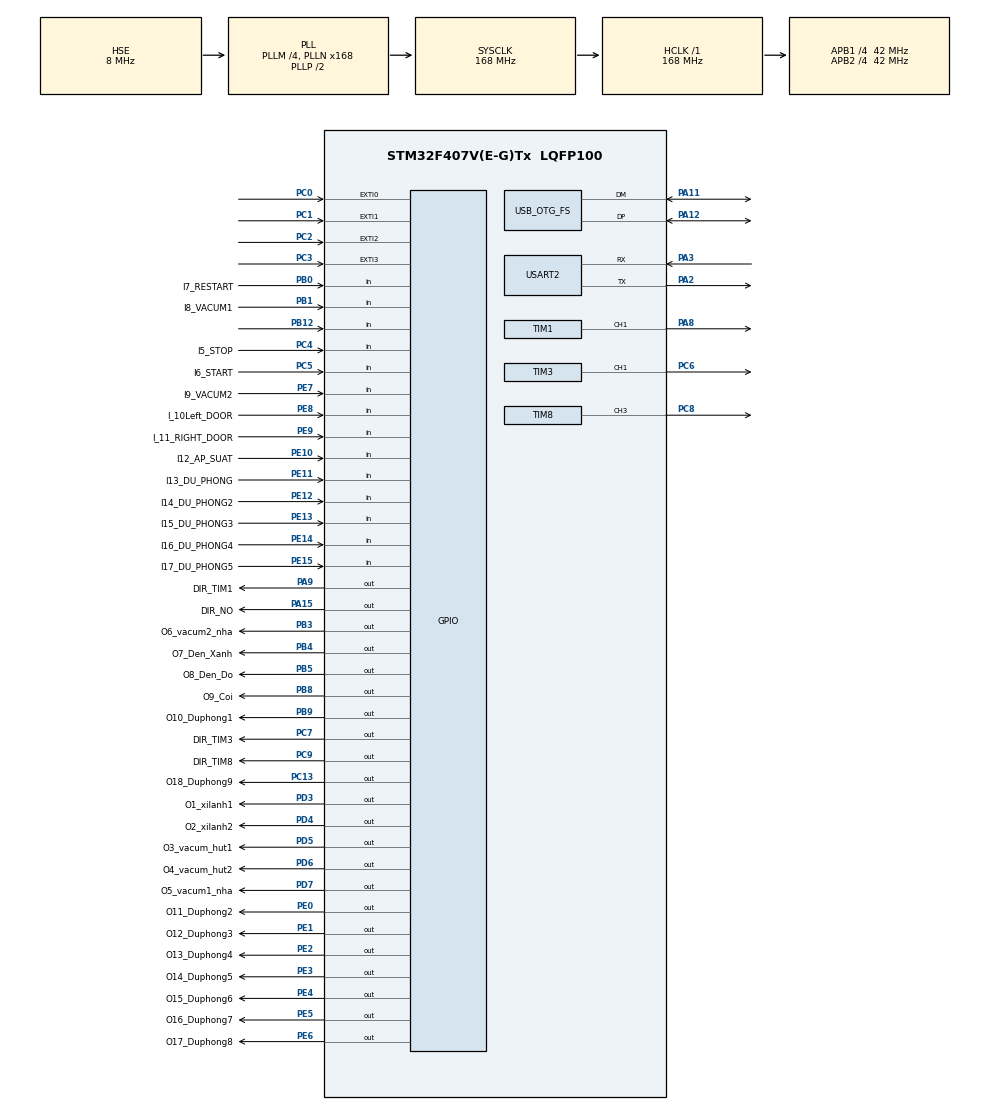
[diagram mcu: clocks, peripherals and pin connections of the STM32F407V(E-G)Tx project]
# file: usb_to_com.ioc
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Dma.Request0=USART2_RX
Dma.Request1=USART2_TX
Dma.USART2_RX.0.Direction=DMA_PERIPH_TO_MEMORY
Dma.USART2_RX.0.FIFOMode=DMA_FIFOMODE_DISABLE
Dma.USART2_RX.0.Instance=DMA1_Stream5
Dma.USART2_RX.0.MemDataAlignment=DMA_MDATAALIGN_BYTE
Dma.USART2_RX.0.MemInc=DMA_MINC_ENABLE
Dma.USART2_RX.0.Mode=DMA_NORMAL
Dma.USART2_RX.0.PeriphDataAlignment=DMA_PDATAALIGN_BYTE
Dma.USART2_RX.0.PeriphInc=DMA_PINC_DISABLE
Dma.USART2_RX.0.Priority=DMA_PRIORITY_LOW
Dma.USART2_TX.1.Direction=DMA_MEMORY_TO_PERIPH
Dma.USART2_TX.1.FIFOMode=DMA_FIFOMODE_DISABLE
Dma.USART2_TX.1.Instance=DMA1_Stream6
Dma.USART2_TX.1.MemDataAlignment=DMA_MDATAALIGN_BYTE
Dma.USART2_TX.1.MemInc=DMA_MINC_ENABLE
Dma.USART2_TX.1.Mode=DMA_NORMAL
Dma.USART2_TX.1.PeriphDataAlignment=DMA_PDATAALIGN_BYTE
Dma.USART2_TX.1.PeriphInc=DMA_PINC_DISABLE
Dma.USART2_TX.1.Priority=DMA_PRIORITY_LOW
Mcu.Family=STM32F4
Mcu.Name=STM32F407V(E-G)Tx
Mcu.Package=LQFP100
NVIC.DMA1_Stream5_IRQn=true\:1\:0\:true\:false\:true\:false\:true\:true
NVIC.DMA1_Stream6_IRQn=true\:1\:0\:true\:false\:true\:false\:true\:true
NVIC.EXTI0_IRQn=true\:0\:0\:false\:false\:true\:true\:true\:true
NVIC.EXTI1_IRQn=true\:0\:0\:false\:false\:true\:true\:true\:true
NVIC.EXTI2_IRQn=true\:0\:0\:false\:false\:true\:true\:true\:true
NVIC.EXTI3_IRQn=true\:0\:0\:false\:false\:true\:true\:true\:true
NVIC.OTG_FS_IRQn=true\:1\:0\:true\:false\:true\:false\:true\:true
NVIC.PriorityGroup=NVIC_PRIORITYGROUP_4
NVIC.TIM7_IRQn=true\:0\:0\:true\:false\:true\:true\:true\:true
NVIC.USART2_IRQn=true\:1\:0\:true\:false\:true\:true\:true\:true
PA11.Mode=Device_Only
PA11.Signal=USB_OTG_FS_DM
PA12.Mode=Device_Only
PA12.Signal=USB_OTG_FS_DP
PA13.Mode=Serial_Wire
PA13.Signal=SYS_JTMS-SWDIO
PA14.Mode=Serial_Wire
PA14.Signal=SYS_JTCK-SWCLK
PA15.GPIO_Label=DIR_NO
PA15.Signal=GPIO_Output
PA2.Mode=Asynchronous
PA2.Signal=USART2_TX
PA3.Mode=Asynchronous
PA3.Signal=USART2_RX
PA8.GPIO_PuPd=GPIO_NOPULL
PA8.GPIO_Speed=GPIO_SPEED_FREQ_HIGH
PA8.Signal=S_TIM1_CH1
PA9.GPIO_Label=DIR_TIM1
PA9.GPIO_Speed=GPIO_SPEED_FREQ_HIGH
PA9.Signal=GPIO_Output
PB0.GPIO_Label=I7_RESTART
PB0.Signal=GPIO_Input
PB1.GPIO_Label=I8_VACUM1
PB1.Signal=GPIO_Input
PB12.Signal=GPIO_Input
PB3.GPIO_Label=O6_vacum2_nha
PB3.GPIO_PuPd=GPIO_PULLUP
PB3.PinState=GPIO_PIN_SET
PB3.Signal=GPIO_Output
PB4.GPIO_Label=O7_Den_Xanh
PB4.GPIO_PuPd=GPIO_PULLUP
PB4.PinState=GPIO_PIN_SET
PB4.Signal=GPIO_Output
PB5.GPIO_Label=O8_Den_Do
PB5.GPIO_PuPd=GPIO_PULLUP
PB5.PinState=GPIO_PIN_SET
PB5.Signal=GPIO_Output
PB8.GPIO_Label=O9_Coi
PB8.GPIO_PuPd=GPIO_PULLUP
PB8.PinState=GPIO_PIN_SET
PB8.Signal=GPIO_Output
PB9.GPIO_Label=O10_Duphong1
PB9.GPIO_PuPd=GPIO_PULLUP
PB9.PinState=GPIO_PIN_SET
PB9.Signal=GPIO_Output
PC0.GPIO_ModeDefaultEXTI=GPIO_MODE_IT_RISING
PC0.Signal=GPXTI0
PC1.GPIO_ModeDefaultEXTI=GPIO_MODE_IT_RISING
PC1.Signal=GPXTI1
PC13-ANTI_TAMP.GPIO_Label=O18_Duphong9
PC13-ANTI_TAMP.GPIO_PuPd=GPIO_PULLUP
PC13-ANTI_TAMP.PinState=GPIO_PIN_SET
PC13-ANTI_TAMP.Signal=GPIO_Output
PC2.GPIO_ModeDefaultEXTI=GPIO_MODE_IT_RISING
PC2.Signal=GPXTI2
PC3.Signal=GPXTI3
PC4.GPIO_Label=I5_STOP
PC4.Signal=GPIO_Input
PC5.GPIO_Label=I6_START
PC5.Signal=GPIO_Input
PC6.GPIO_PuPd=GPIO_NOPULL
PC6.GPIO_Speed=GPIO_SPEED_FREQ_HIGH
PC6.Signal=S_TIM3_CH1
PC7.GPIO_Label=DIR_TIM3
PC7.GPIO_Speed=GPIO_SPEED_FREQ_HIGH
PC7.Signal=GPIO_Output
PC8.GPIO_ModeDefaultPP=GPIO_MODE_AF_PP
PC8.GPIO_PuPd=GPIO_NOPULL
PC8.GPIO_Speed=GPIO_SPEED_FREQ_HIGH
PC8.Signal=S_TIM8_CH3
PC9.GPIO_Label=DIR_TIM8
PC9.GPIO_Speed=GPIO_SPEED_FREQ_HIGH
PC9.Signal=GPIO_Output
PD3.GPIO_Label=O1_xilanh1
PD3.GPIO_PuPd=GPIO_PULLUP
PD3.PinState=GPIO_PIN_SET
PD3.Signal=GPIO_Output
PD4.GPIO_Label=O2_xilanh2
PD4.GPIO_PuPd=GPIO_PULLUP
PD4.PinState=GPIO_PIN_SET
PD4.Signal=GPIO_Output
PD5.GPIO_Label=O3_vacum_hut1
PD5.GPIO_PuPd=GPIO_PULLUP
PD5.PinState=GPIO_PIN_SET
PD5.Signal=GPIO_Output
PD6.GPIO_Label=O4_vacum_hut2
PD6.GPIO_PuPd=GPIO_PULLUP
PD6.PinState=GPIO_PIN_SET
PD6.Signal=GPIO_Output
PD7.GPIO_Label=O5_vacum1_nha
PD7.GPIO_PuPd=GPIO_PULLUP
PD7.PinState=GPIO_PIN_SET
PD7.Signal=GPIO_Output
PE0.GPIO_Label=O11_Duphong2
PE0.GPIO_PuPd=GPIO_PULLUP
PE0.PinState=GPIO_PIN_SET
PE0.Signal=GPIO_Output
PE1.GPIO_Label=O12_Duphong3
PE1.GPIO_PuPd=GPIO_PULLUP
PE1.PinState=GPIO_PIN_SET
PE1.Signal=GPIO_Output
PE10.GPIO_Label=I12_AP_SUAT
PE10.GPIO_PuPd=GPIO_NOPULL
PE10.Signal=GPIO_Input
PE11.GPIO_Label=I13_DU_PHONG
PE11.GPIO_PuPd=GPIO_NOPULL
PE11.Signal=GPIO_Input
PE12.GPIO_Label=I14_DU_PHONG2
PE12.GPIO_PuPd=GPIO_NOPULL
PE12.Signal=GPIO_Input
PE13.GPIO_Label=I15_DU_PHONG3
PE13.Signal=GPIO_Input
PE14.GPIO_Label=I16_DU_PHONG4
PE14.Signal=GPIO_Input
PE15.GPIO_Label=I17_DU_PHONG5
PE15.Signal=GPIO_Input
PE2.GPIO_Label=O13_Duphong4
PE2.GPIO_PuPd=GPIO_PULLUP
PE2.PinState=GPIO_PIN_SET
PE2.Signal=GPIO_Output
PE3.GPIO_Label=O14_Duphong5
PE3.GPIO_PuPd=GPIO_PULLUP
PE3.PinState=GPIO_PIN_SET
PE3.Signal=GPIO_Output
PE4.GPIO_Label=O15_Duphong6
PE4.GPIO_PuPd=GPIO_PULLUP
PE4.PinState=GPIO_PIN_SET
PE4.Signal=GPIO_Output
PE5.GPIO_Label=O16_Duphong7
PE5.GPIO_PuPd=GPIO_PULLUP
PE5.PinState=GPIO_PIN_SET
PE5.Signal=GPIO_Output
PE6.GPIO_Label=O17_Duphong8
PE6.GPIO_PuPd=GPIO_PULLUP
PE6.PinState=GPIO_PIN_SET
PE6.Signal=GPIO_Output
PE7.GPIO_Label=I9_VACUM2
PE7.GPIO_PuPd=GPIO_NOPULL
PE7.Signal=GPIO_Input
PE8.GPIO_Label=I_10Left_DOOR
PE8.GPIO_PuPd=GPIO_NOPULL
PE8.Signal=GPIO_Input
PE9.GPIO_Label=I_11_RIGHT_DOOR
PE9.GPIO_PuPd=GPIO_NOPULL
PE9.Signal=GPIO_Input
PH0-OSC_IN.Mode=HSE-External-Oscillator
PH0-OSC_IN.Signal=RCC_OSC_IN
PH1-OSC_OUT.Mode=HSE-External-Oscillator
PH1-OSC_OUT.Signal=RCC_OSC_OUT
ProjectManager.HeapSize=0x200
ProjectManager.StackSize=0x400
ProjectManager.TargetToolchain=STM32CubeIDE
RCC.48MHZClocksFreq_Value=48000000
RCC.AHBFreq_Value=168000000
RCC.APB1CLKDivider=RCC_HCLK_DIV4
RCC.APB1Freq_Value=42000000
RCC.APB1TimFreq_Value=84000000
RCC.APB2CLKDivider=RCC_HCLK_DIV4
RCC.APB2Freq_Value=42000000
RCC.APB2TimFreq_Value=84000000
RCC.CortexFreq_Value=168000000
RCC.HCLKFreq_Value=168000000
RCC.HSE_VALUE=8000000
RCC.HSI_VALUE=16000000
RCC.LSE_VALUE=32768
RCC.PLLM=4
RCC.PLLN=168
RCC.PLLQ=7
RCC.PLLSourceVirtual=RCC_PLLSOURCE_HSE
RCC.SYSCLKFreq_VALUE=168000000
RCC.SYSCLKSource=RCC_SYSCLKSOURCE_PLLCLK
RCC.VCOOutputFreq_Value=336000000
SH.S_TIM1_CH1.0=TIM1_CH1,PWM Generation1 CH1
SH.S_TIM3_CH1.0=TIM3_CH1,PWM Generation1 CH1
SH.S_TIM8_CH3.0=TIM8_CH3,PWM Generation3 CH3
TIM1.AutoReloadPreload=TIM_AUTORELOAD_PRELOAD_ENABLE
TIM1.Channel-PWM\ Generation1\ CH1=TIM_CHANNEL_1
TIM1.OCMode_PWM-PWM\ Generation1\ CH1=TIM_OCMODE_PWM1
TIM1.Period=1999
TIM1.Prescaler=83
TIM1.Pulse-PWM\ Generation1\ CH1=0
TIM1.TIM_MasterOutputTrigger=TIM_TRGO_OC1REF
TIM1.TIM_MasterSlaveMode=TIM_MASTERSLAVEMODE_ENABLE
TIM2.AutoReloadPreload=TIM_AUTORELOAD_PRELOAD_ENABLE
TIM2.Channel-PWM\ Generation2\ No\ Output=TIM_CHANNEL_2
TIM2.OCPolarity_2=TIM_OCPOLARITY_HIGH
TIM2.Period=999
TIM2.Prescaler=0
TIM2.Pulse-PWM\ Generation2\ No\ Output=0
TIM2.TIM_MasterOutputTrigger=TIM_TRGO_OC2REF
TIM2.TIM_MasterSlaveMode=TIM_MASTERSLAVEMODE_ENABLE
TIM3.AutoReloadPreload=TIM_AUTORELOAD_PRELOAD_ENABLE
TIM3.Channel-PWM\ Generation1\ CH1=TIM_CHANNEL_1
TIM3.Period=1999
TIM3.Prescaler=83
TIM3.Pulse-PWM\ Generation1\ CH1=0
TIM3.TIM_MasterOutputTrigger=TIM_TRGO_OC1REF
TIM3.TIM_MasterSlaveMode=TIM_MASTERSLAVEMODE_ENABLE
TIM4.AutoReloadPreload=TIM_AUTORELOAD_PRELOAD_ENABLE
TIM4.Channel-PWM\ Generation1\ No\ Output=TIM_CHANNEL_1
TIM4.OCPolarity_1=TIM_OCPOLARITY_HIGH
TIM4.Period=999
TIM4.Prescaler=0
TIM4.Pulse-PWM\ Generation1\ No\ Output=0
TIM4.TIM_MasterOutputTrigger=TIM_TRGO_OC1REF
TIM4.TIM_MasterSlaveMode=TIM_MASTERSLAVEMODE_ENABLE
TIM5.AutoReloadPreload=TIM_AUTORELOAD_PRELOAD_ENABLE
TIM5.Channel-PWM\ Generation1\ No\ Output=TIM_CHANNEL_1
TIM5.OCPolarity_1=TIM_OCPOLARITY_HIGH
TIM5.Period=999
TIM5.Pulse-PWM\ Generation1\ No\ Output=0
TIM5.TIM_MasterOutputTrigger=TIM_TRGO_OC1REF
TIM5.TIM_MasterSlaveMode=TIM_MASTERSLAVEMODE_ENABLE
TIM7.AutoReloadPreload=TIM_AUTORELOAD_PRELOAD_ENABLE
TIM7.Period=999
TIM7.Prescaler=83
TIM8.AutoReloadPreload=TIM_AUTORELOAD_PRELOAD_ENABLE
TIM8.Channel-PWM\ Generation3\ CH3=TIM_CHANNEL_3
TIM8.OCPolarity_3=TIM_OCPOLARITY_HIGH
TIM8.Period=999
TIM8.Prescaler=83
TIM8.Pulse-PWM\ Generation3\ CH3=0
TIM8.TIM_MasterOutputTrigger=TIM_TRGO_OC3REF
TIM8.TIM_MasterSlaveMode=TIM_MASTERSLAVEMODE_ENABLE
USART2.VirtualMode=VM_ASYNC
USB_DEVICE.CLASS_NAME_FS=CDC
USB_DEVICE.VirtualMode-CDC_FS=Cdc
USB_DEVICE.VirtualModeFS=Cdc_FS
USB_OTG_FS.VirtualMode=Device_Only
VP_TIM1_VS_ClockSourceINT.Mode=Internal
VP_TIM1_VS_ClockSourceITR.Mode=TriggerSource_ITR1
VP_TIM1_VS_ControllerModeGated.Mode=Gated Mode
VP_TIM2_VS_ClockSourceITR.Mode=TriggerSource_ITR0
VP_TIM2_VS_ControllerModeClock.Mode=Clock Mode
VP_TIM2_VS_no_output2.Mode=PWM Generation2 No Output
VP_TIM3_VS_ClockSourceINT.Mode=Internal
VP_TIM3_VS_ClockSourceITR.Mode=TriggerSource_ITR2
VP_TIM3_VS_ControllerModeGated.Mode=Gated Mode
VP_TIM4_VS_ClockSourceITR.Mode=TriggerSource_ITR3
VP_TIM4_VS_ControllerModeClock.Mode=Clock Mode
VP_TIM4_VS_no_output1.Mode=PWM Generation1 No Output
VP_TIM5_VS_ClockSourceITR.Mode=TriggerSource_ITR1
VP_TIM5_VS_ControllerModeClock.Mode=Clock Mode
VP_TIM5_VS_no_output1.Mode=PWM Generation1 No Output
VP_TIM7_VS_ClockSourceINT.Mode=Enable_Timer
VP_TIM8_VS_ClockSourceINT.Mode=Internal
VP_TIM8_VS_ClockSourceITR.Mode=TriggerSource_ITR2
VP_TIM8_VS_ControllerModeGated.Mode=Gated Mode
VP_USB_DEVICE_VS_USB_DEVICE_CDC_FS.Mode=CDC_FS
board=custom

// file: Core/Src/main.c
/* USER CODE BEGIN Header */
/**
  ******************************************************************************
  * @file           : main.c
  * @brief          : Main program body
  ******************************************************************************
  * @attention
  *
  * Copyright (c) 2026 STMicroelectronics.
  * All rights reserved.
  *
  * This software is licensed under terms that can be found in the LICENSE file
  * in the root directory of this software component.
  * If no LICENSE file comes with this software, it is provided AS-IS.
  *
  ******************************************************************************
  */
/* USER CODE END Header */
#include "main.h"
#include "usb_device.h"

/* USER CODE BEGIN Includes */
//#include "usb_device.h"
#include "drive.h"
#include"drive_time.h"
#include "RS232.h"
#include "mgr_hmi.h"
#include "flash_data.h"
#include"dvr_gpio.h"
#include <string.h>
/* USER CODE END Includes */

TIM_HandleTypeDef htim1;
TIM_HandleTypeDef htim2;
TIM_HandleTypeDef htim3;
TIM_HandleTypeDef htim4;
TIM_HandleTypeDef htim5;
TIM_HandleTypeDef htim7;
TIM_HandleTypeDef htim8;

UART_HandleTypeDef huart2;
DMA_HandleTypeDef hdma_usart2_rx;
DMA_HandleTypeDef hdma_usart2_tx;

/* USER CODE BEGIN PV */
TIM_HandleTypeDef htim9;
/* USER CODE END PV */

void SystemClock_Config(void);
static void MX_GPIO_Init(void);
static void MX_DMA_Init(void);
static void MX_TIM1_Init(void);
static void MX_TIM3_Init(void);
static void MX_TIM4_Init(void);
static void MX_TIM2_Init(void);
static void MX_TIM8_Init(void);
static void MX_TIM5_Init(void);
static void MX_TIM7_Init(void);
static void MX_USART2_UART_Init(void);
/* USER CODE BEGIN PFP */
uint8_t time_on=0x00;
uint8_t local_buf[RX_BUF_SIZE];
uint32_t max_ticks_main=0x00U;
/* USER CODE END PFP */

int main(void)
{

  /* MCU Configuration--------------------------------------------------------*/

  /* Reset of all peripherals, Initializes the Flash interface and the Systick. */
  HAL_Init();

  /* Configure the system clock */
  SystemClock_Config();

  /* Initialize all configured peripherals */
  MX_GPIO_Init();
  MX_DMA_Init();
  MX_TIM1_Init();
  MX_TIM3_Init();
  MX_TIM4_Init();
  MX_TIM2_Init();
  MX_TIM8_Init();
  MX_TIM5_Init();
  MX_TIM7_Init();
  MX_USART2_UART_Init();
  MX_USB_DEVICE_Init();
  /* USER CODE BEGIN 2 */
  Init_Timer_chanal();
  Robot_Init();
  Delay_SetTimer(TID_TIMER_1ms,0x01U);
  Delay_SetTimer(TID_TIMER_2ms,0x02U);
  HMI_Init();
  Debug_init();
  HAL_TIM_Base_Start_IT(&htim7);
  HAL_Delay(1000);
//  GPIOA ->ODR |=(1<<10U);
  /* USER CODE END 2 */

  /* Infinite loop */
  /* USER CODE BEGIN WHILE */
  while (1)
  {
	  	 // bổ sung watdog sau khi chạy ok
		#ifdef PROCES_IN_MAIN
			if(is_new_frame==0x01U)
			{
				uint32_t start_tick = DWT->CYCCNT; // Lấy số tick lúc bắt đầu
				// 1. Lưu trạng thái ngắt cũ
				uint32_t primask_bit = __get_PRIMASK();
				// 2. Chặn ngắt để bảo vệ quá trình đ�?c
				__disable_irq();
				// 3. Thực hiện copy dữ liệu một cách an toàn
				memcpy(local_buf, ProcessBuf, leng_size);
				is_new_frame = 0U; // Reset c�? báo
				// 4. Khôi phục ngắt (đưa v�? trạng thái ban đầu)
				__set_PRIMASK(primask_bit);
				Modbus_Rtu_Run(local_buf,leng_size);
				uint32_t end_tick = DWT->CYCCNT;   // Lấy số tick lúc kết thúc
				uint32_t execution_ticks = end_tick - start_tick;
				if (execution_ticks > max_ticks_main) {
					max_ticks_main = execution_ticks; // Lưu lại kỷ lục chậm nhất
				}
			}
		#endif
		time_on=Delay_GetTimer(TID_TIMER_1ms);
		if(time_on==0x01)
		{
			Task_Run_HMI();
			Task_Run_Home();
#ifdef MAIN_CONTROLLER
			Task_Main_Controler();
#endif
		}
		time_on=Delay_GetTimer(TID_TIMER_2ms);// cập nhập giá trị in out lên modbus
		if(time_on==0x01)
		{
			Task_gpio_input();
			Task_gpio_output();
		}
    /* USER CODE END WHILE */

  }
}

void SystemClock_Config(void)
{
  RCC_OscInitTypeDef RCC_OscInitStruct = {0};
  RCC_ClkInitTypeDef RCC_ClkInitStruct = {0};

  /** Configure the main internal regulator output voltage
  */
  __HAL_RCC_PWR_CLK_ENABLE();
  __HAL_PWR_VOLTAGESCALING_CONFIG(PWR_REGULATOR_VOLTAGE_SCALE1);

  /** Initializes the RCC Oscillators according to the specified parameters
  * in the RCC_OscInitTypeDef structure.
  */
  RCC_OscInitStruct.OscillatorType = RCC_OSCILLATORTYPE_HSE;
  RCC_OscInitStruct.HSEState = RCC_HSE_ON;
  RCC_OscInitStruct.PLL.PLLState = RCC_PLL_ON;
  RCC_OscInitStruct.PLL.PLLSource = RCC_PLLSOURCE_HSE;
  RCC_OscInitStruct.PLL.PLLM = 4;
  RCC_OscInitStruct.PLL.PLLN = 168;
  RCC_OscInitStruct.PLL.PLLP = RCC_PLLP_DIV2;
  RCC_OscInitStruct.PLL.PLLQ = 7;
  if (HAL_RCC_OscConfig(&RCC_OscInitStruct) != HAL_OK)
  {
    Error_Handler();
  }

  /** Initializes the CPU, AHB and APB buses clocks
  */
  RCC_ClkInitStruct.ClockType = RCC_CLOCKTYPE_HCLK|RCC_CLOCKTYPE_SYSCLK
                              |RCC_CLOCKTYPE_PCLK1|RCC_CLOCKTYPE_PCLK2;
  RCC_ClkInitStruct.SYSCLKSource = RCC_SYSCLKSOURCE_PLLCLK;
  RCC_ClkInitStruct.AHBCLKDivider = RCC_SYSCLK_DIV1;
  RCC_ClkInitStruct.APB1CLKDivider = RCC_HCLK_DIV4;
  RCC_ClkInitStruct.APB2CLKDivider = RCC_HCLK_DIV4;

  if (HAL_RCC_ClockConfig(&RCC_ClkInitStruct, FLASH_LATENCY_5) != HAL_OK)
  {
    Error_Handler();
  }
}

static void MX_TIM1_Init(void)
{

  TIM_ClockConfigTypeDef sClockSourceConfig = {0};
  TIM_SlaveConfigTypeDef sSlaveConfig = {0};
  TIM_MasterConfigTypeDef sMasterConfig = {0};
  TIM_OC_InitTypeDef sConfigOC = {0};
  TIM_BreakDeadTimeConfigTypeDef sBreakDeadTimeConfig = {0};

  htim1.Instance = TIM1;
  htim1.Init.Prescaler = 83;
  htim1.Init.CounterMode = TIM_COUNTERMODE_UP;
  htim1.Init.Period = 1999;
  htim1.Init.ClockDivision = TIM_CLOCKDIVISION_DIV1;
  htim1.Init.RepetitionCounter = 0;
  htim1.Init.AutoReloadPreload = TIM_AUTORELOAD_PRELOAD_ENABLE;
  if (HAL_TIM_Base_Init(&htim1) != HAL_OK)
  {
    Error_Handler();
  }
  sClockSourceConfig.ClockSource = TIM_CLOCKSOURCE_INTERNAL;
  if (HAL_TIM_ConfigClockSource(&htim1, &sClockSourceConfig) != HAL_OK)
  {
    Error_Handler();
  }
  if (HAL_TIM_PWM_Init(&htim1) != HAL_OK)
  {
    Error_Handler();
  }
  sSlaveConfig.SlaveMode = TIM_SLAVEMODE_GATED;
  sSlaveConfig.InputTrigger = TIM_TS_ITR1;
  if (HAL_TIM_SlaveConfigSynchro(&htim1, &sSlaveConfig) != HAL_OK)
  {
    Error_Handler();
  }
  sMasterConfig.MasterOutputTrigger = TIM_TRGO_OC1REF;
  sMasterConfig.MasterSlaveMode = TIM_MASTERSLAVEMODE_ENABLE;
  if (HAL_TIMEx_MasterConfigSynchronization(&htim1, &sMasterConfig) != HAL_OK)
  {
    Error_Handler();
  }
  sConfigOC.OCMode = TIM_OCMODE_PWM1;
  sConfigOC.Pulse = 0;
  sConfigOC.OCPolarity = TIM_OCPOLARITY_HIGH;
  sConfigOC.OCNPolarity = TIM_OCNPOLARITY_HIGH;
  sConfigOC.OCFastMode = TIM_OCFAST_DISABLE;
  sConfigOC.OCIdleState = TIM_OCIDLESTATE_RESET;
  sConfigOC.OCNIdleState = TIM_OCNIDLESTATE_RESET;
  if (HAL_TIM_PWM_ConfigChannel(&htim1, &sConfigOC, TIM_CHANNEL_1) != HAL_OK)
  {
    Error_Handler();
  }
  sBreakDeadTimeConfig.OffStateRunMode = TIM_OSSR_DISABLE;
  sBreakDeadTimeConfig.OffStateIDLEMode = TIM_OSSI_DISABLE;
  sBreakDeadTimeConfig.LockLevel = TIM_LOCKLEVEL_OFF;
  sBreakDeadTimeConfig.DeadTime = 0;
  sBreakDeadTimeConfig.BreakState = TIM_BREAK_DISABLE;
  sBreakDeadTimeConfig.BreakPolarity = TIM_BREAKPOLARITY_HIGH;
  sBreakDeadTimeConfig.AutomaticOutput = TIM_AUTOMATICOUTPUT_DISABLE;
  if (HAL_TIMEx_ConfigBreakDeadTime(&htim1, &sBreakDeadTimeConfig) != HAL_OK)
  {
    Error_Handler();
  }
  HAL_TIM_MspPostInit(&htim1);

}

static void MX_TIM2_Init(void)
{

  TIM_SlaveConfigTypeDef sSlaveConfig = {0};
  TIM_MasterConfigTypeDef sMasterConfig = {0};
  TIM_OC_InitTypeDef sConfigOC = {0};

  htim2.Instance = TIM2;
  htim2.Init.Prescaler = 0;
  htim2.Init.CounterMode = TIM_COUNTERMODE_UP;
  htim2.Init.Period = 999;
  htim2.Init.ClockDivision = TIM_CLOCKDIVISION_DIV1;
  htim2.Init.AutoReloadPreload = TIM_AUTORELOAD_PRELOAD_ENABLE;
  if (HAL_TIM_Base_Init(&htim2) != HAL_OK)
  {
    Error_Handler();
  }
  if (HAL_TIM_PWM_Init(&htim2) != HAL_OK)
  {
    Error_Handler();
  }
  sSlaveConfig.SlaveMode = TIM_SLAVEMODE_EXTERNAL1;
  sSlaveConfig.InputTrigger = TIM_TS_ITR0;
  if (HAL_TIM_SlaveConfigSynchro(&htim2, &sSlaveConfig) != HAL_OK)
  {
    Error_Handler();
  }
  sMasterConfig.MasterOutputTrigger = TIM_TRGO_OC2REF;
  sMasterConfig.MasterSlaveMode = TIM_MASTERSLAVEMODE_ENABLE;
  if (HAL_TIMEx_MasterConfigSynchronization(&htim2, &sMasterConfig) != HAL_OK)
  {
    Error_Handler();
  }
  sConfigOC.OCMode = TIM_OCMODE_PWM1;
  sConfigOC.Pulse = 0;
  sConfigOC.OCPolarity = TIM_OCPOLARITY_HIGH;
  sConfigOC.OCFastMode = TIM_OCFAST_DISABLE;
  if (HAL_TIM_PWM_ConfigChannel(&htim2, &sConfigOC, TIM_CHANNEL_2) != HAL_OK)
  {
    Error_Handler();
  }

}

static void MX_TIM3_Init(void)
{

  TIM_ClockConfigTypeDef sClockSourceConfig = {0};
  TIM_SlaveConfigTypeDef sSlaveConfig = {0};
  TIM_MasterConfigTypeDef sMasterConfig = {0};
  TIM_OC_InitTypeDef sConfigOC = {0};

  htim3.Instance = TIM3;
  htim3.Init.Prescaler = 83;
  htim3.Init.CounterMode = TIM_COUNTERMODE_UP;
  htim3.Init.Period = 1999;
  htim3.Init.ClockDivision = TIM_CLOCKDIVISION_DIV1;
  htim3.Init.AutoReloadPreload = TIM_AUTORELOAD_PRELOAD_ENABLE;
  if (HAL_TIM_Base_Init(&htim3) != HAL_OK)
  {
    Error_Handler();
  }
  sClockSourceConfig.ClockSource = TIM_CLOCKSOURCE_INTERNAL;
  if (HAL_TIM_ConfigClockSource(&htim3, &sClockSourceConfig) != HAL_OK)
  {
    Error_Handler();
  }
  if (HAL_TIM_PWM_Init(&htim3) != HAL_OK)
  {
    Error_Handler();
  }
  sSlaveConfig.SlaveMode = TIM_SLAVEMODE_GATED;
  sSlaveConfig.InputTrigger = TIM_TS_ITR2;
  if (HAL_TIM_SlaveConfigSynchro(&htim3, &sSlaveConfig) != HAL_OK)
  {
    Error_Handler();
  }
  sMasterConfig.MasterOutputTrigger = TIM_TRGO_OC1REF;
  sMasterConfig.MasterSlaveMode = TIM_MASTERSLAVEMODE_ENABLE;
  if (HAL_TIMEx_MasterConfigSynchronization(&htim3, &sMasterConfig) != HAL_OK)
  {
    Error_Handler();
  }
  sConfigOC.OCMode = TIM_OCMODE_PWM1;
  sConfigOC.Pulse = 0;
  sConfigOC.OCPolarity = TIM_OCPOLARITY_HIGH;
  sConfigOC.OCFastMode = TIM_OCFAST_DISABLE;
  if (HAL_TIM_PWM_ConfigChannel(&htim3, &sConfigOC, TIM_CHANNEL_1) != HAL_OK)
  {
    Error_Handler();
  }
  HAL_TIM_MspPostInit(&htim3);

}

static void MX_TIM4_Init(void)
{

  TIM_SlaveConfigTypeDef sSlaveConfig = {0};
  TIM_MasterConfigTypeDef sMasterConfig = {0};
  TIM_OC_InitTypeDef sConfigOC = {0};

  htim4.Instance = TIM4;
  htim4.Init.Prescaler = 0;
  htim4.Init.CounterMode = TIM_COUNTERMODE_UP;
  htim4.Init.Period = 999;
  htim4.Init.ClockDivision = TIM_CLOCKDIVISION_DIV1;
  htim4.Init.AutoReloadPreload = TIM_AUTORELOAD_PRELOAD_ENABLE;
  if (HAL_TIM_Base_Init(&htim4) != HAL_OK)
  {
    Error_Handler();
  }
  if (HAL_TIM_PWM_Init(&htim4) != HAL_OK)
  {
    Error_Handler();
  }
  sSlaveConfig.SlaveMode = TIM_SLAVEMODE_EXTERNAL1;
  sSlaveConfig.InputTrigger = TIM_TS_ITR3;
  if (HAL_TIM_SlaveConfigSynchro(&htim4, &sSlaveConfig) != HAL_OK)
  {
    Error_Handler();
  }
  sMasterConfig.MasterOutputTrigger = TIM_TRGO_OC1REF;
  sMasterConfig.MasterSlaveMode = TIM_MASTERSLAVEMODE_ENABLE;
  if (HAL_TIMEx_MasterConfigSynchronization(&htim4, &sMasterConfig) != HAL_OK)
  {
    Error_Handler();
  }
  sConfigOC.OCMode = TIM_OCMODE_PWM1;
  sConfigOC.Pulse = 0;
  sConfigOC.OCPolarity = TIM_OCPOLARITY_HIGH;
  sConfigOC.OCFastMode = TIM_OCFAST_DISABLE;
  if (HAL_TIM_PWM_ConfigChannel(&htim4, &sConfigOC, TIM_CHANNEL_1) != HAL_OK)
  {
    Error_Handler();
  }

}

static void MX_TIM5_Init(void)
{

  TIM_SlaveConfigTypeDef sSlaveConfig = {0};
  TIM_MasterConfigTypeDef sMasterConfig = {0};
  TIM_OC_InitTypeDef sConfigOC = {0};

  htim5.Instance = TIM5;
  htim5.Init.Prescaler = 0;
  htim5.Init.CounterMode = TIM_COUNTERMODE_UP;
  htim5.Init.Period = 999;
  htim5.Init.ClockDivision = TIM_CLOCKDIVISION_DIV1;
  htim5.Init.AutoReloadPreload = TIM_AUTORELOAD_PRELOAD_ENABLE;
  if (HAL_TIM_Base_Init(&htim5) != HAL_OK)
  {
    Error_Handler();
  }
  if (HAL_TIM_PWM_Init(&htim5) != HAL_OK)
  {
    Error_Handler();
  }
  sSlaveConfig.SlaveMode = TIM_SLAVEMODE_EXTERNAL1;
  sSlaveConfig.InputTrigger = TIM_TS_ITR1;
  if (HAL_TIM_SlaveConfigSynchro(&htim5, &sSlaveConfig) != HAL_OK)
  {
    Error_Handler();
  }
  sMasterConfig.MasterOutputTrigger = TIM_TRGO_OC1REF;
  sMasterConfig.MasterSlaveMode = TIM_MASTERSLAVEMODE_ENABLE;
  if (HAL_TIMEx_MasterConfigSynchronization(&htim5, &sMasterConfig) != HAL_OK)
  {
    Error_Handler();
  }
  sConfigOC.OCMode = TIM_OCMODE_PWM1;
  sConfigOC.Pulse = 0;
  sConfigOC.OCPolarity = TIM_OCPOLARITY_HIGH;
  sConfigOC.OCFastMode = TIM_OCFAST_DISABLE;
  if (HAL_TIM_PWM_ConfigChannel(&htim5, &sConfigOC, TIM_CHANNEL_1) != HAL_OK)
  {
    Error_Handler();
  }

}

static void MX_TIM7_Init(void)
{

  TIM_MasterConfigTypeDef sMasterConfig = {0};

  htim7.Instance = TIM7;
  htim7.Init.Prescaler = 83;
  htim7.Init.CounterMode = TIM_COUNTERMODE_UP;
  htim7.Init.Period = 999;
  htim7.Init.AutoReloadPreload = TIM_AUTORELOAD_PRELOAD_ENABLE;
  if (HAL_TIM_Base_Init(&htim7) != HAL_OK)
  {
    Error_Handler();
  }
  sMasterConfig.MasterOutputTrigger = TIM_TRGO_RESET;
  sMasterConfig.MasterSlaveMode = TIM_MASTERSLAVEMODE_DISABLE;
  if (HAL_TIMEx_MasterConfigSynchronization(&htim7, &sMasterConfig) != HAL_OK)
  {
    Error_Handler();
  }

}

static void MX_TIM8_Init(void)
{

  TIM_ClockConfigTypeDef sClockSourceConfig = {0};
  TIM_SlaveConfigTypeDef sSlaveConfig = {0};
  TIM_MasterConfigTypeDef sMasterConfig = {0};
  TIM_OC_InitTypeDef sConfigOC = {0};
  TIM_BreakDeadTimeConfigTypeDef sBreakDeadTimeConfig = {0};

  htim8.Instance = TIM8;
  htim8.Init.Prescaler = 83;
  htim8.Init.CounterMode = TIM_COUNTERMODE_UP;
  htim8.Init.Period = 999;
  htim8.Init.ClockDivision = TIM_CLOCKDIVISION_DIV1;
  htim8.Init.RepetitionCounter = 0;
  htim8.Init.AutoReloadPreload = TIM_AUTORELOAD_PRELOAD_ENABLE;
  if (HAL_TIM_Base_Init(&htim8) != HAL_OK)
  {
    Error_Handler();
  }
  sClockSourceConfig.ClockSource = TIM_CLOCKSOURCE_INTERNAL;
  if (HAL_TIM_ConfigClockSource(&htim8, &sClockSourceConfig) != HAL_OK)
  {
    Error_Handler();
  }
  if (HAL_TIM_PWM_Init(&htim8) != HAL_OK)
  {
    Error_Handler();
  }
  sSlaveConfig.SlaveMode = TIM_SLAVEMODE_GATED;
  sSlaveConfig.InputTrigger = TIM_TS_ITR2;
  if (HAL_TIM_SlaveConfigSynchro(&htim8, &sSlaveConfig) != HAL_OK)
  {
    Error_Handler();
  }
  sMasterConfig.MasterOutputTrigger = TIM_TRGO_OC3REF;
  sMasterConfig.MasterSlaveMode = TIM_MASTERSLAVEMODE_ENABLE;
  if (HAL_TIMEx_MasterConfigSynchronization(&htim8, &sMasterConfig) != HAL_OK)
  {
    Error_Handler();
  }
  sConfigOC.OCMode = TIM_OCMODE_PWM1;
  sConfigOC.Pulse = 0;
  sConfigOC.OCPolarity = TIM_OCPOLARITY_HIGH;
  sConfigOC.OCNPolarity = TIM_OCNPOLARITY_HIGH;
  sConfigOC.OCFastMode = TIM_OCFAST_DISABLE;
  sConfigOC.OCIdleState = TIM_OCIDLESTATE_RESET;
  sConfigOC.OCNIdleState = TIM_OCNIDLESTATE_RESET;
  if (HAL_TIM_PWM_ConfigChannel(&htim8, &sConfigOC, TIM_CHANNEL_3) != HAL_OK)
  {
    Error_Handler();
  }
  sBreakDeadTimeConfig.OffStateRunMode = TIM_OSSR_DISABLE;
  sBreakDeadTimeConfig.OffStateIDLEMode = TIM_OSSI_DISABLE;
  sBreakDeadTimeConfig.LockLevel = TIM_LOCKLEVEL_OFF;
  sBreakDeadTimeConfig.DeadTime = 0;
  sBreakDeadTimeConfig.BreakState = TIM_BREAK_DISABLE;
  sBreakDeadTimeConfig.BreakPolarity = TIM_BREAKPOLARITY_HIGH;
  sBreakDeadTimeConfig.AutomaticOutput = TIM_AUTOMATICOUTPUT_DISABLE;
  if (HAL_TIMEx_ConfigBreakDeadTime(&htim8, &sBreakDeadTimeConfig) != HAL_OK)
  {
    Error_Handler();
  }
  HAL_TIM_MspPostInit(&htim8);

}

static void MX_USART2_UART_Init(void)
{

  huart2.Instance = USART2;
  huart2.Init.BaudRate = 115200;
  huart2.Init.WordLength = UART_WORDLENGTH_8B;
  huart2.Init.StopBits = UART_STOPBITS_1;
  huart2.Init.Parity = UART_PARITY_NONE;
  huart2.Init.Mode = UART_MODE_TX_RX;
  huart2.Init.HwFlowCtl = UART_HWCONTROL_NONE;
  huart2.Init.OverSampling = UART_OVERSAMPLING_16;
  if (HAL_UART_Init(&huart2) != HAL_OK)
  {
    Error_Handler();
  }

}

static void MX_DMA_Init(void)
{

  /* DMA controller clock enable */
  __HAL_RCC_DMA1_CLK_ENABLE();

  /* DMA interrupt init */
  /* DMA1_Stream5_IRQn interrupt configuration */
  HAL_NVIC_SetPriority(DMA1_Stream5_IRQn, 1, 0);
  HAL_NVIC_EnableIRQ(DMA1_Stream5_IRQn);
  /* DMA1_Stream6_IRQn interrupt configuration */
  HAL_NVIC_SetPriority(DMA1_Stream6_IRQn, 1, 0);
  HAL_NVIC_EnableIRQ(DMA1_Stream6_IRQn);

}

static void MX_GPIO_Init(void)
{
  GPIO_InitTypeDef GPIO_InitStruct = {0};

  /* GPIO Ports Clock Enable */
  __HAL_RCC_GPIOE_CLK_ENABLE();
  __HAL_RCC_GPIOC_CLK_ENABLE();
  __HAL_RCC_GPIOH_CLK_ENABLE();
  __HAL_RCC_GPIOA_CLK_ENABLE();
  __HAL_RCC_GPIOB_CLK_ENABLE();
  __HAL_RCC_GPIOD_CLK_ENABLE();

  /*Configure GPIO pin Output Level */
  HAL_GPIO_WritePin(GPIOE, O13_Duphong4_Pin|O14_Duphong5_Pin|O15_Duphong6_Pin|O16_Duphong7_Pin
                          |O17_Duphong8_Pin|O11_Duphong2_Pin|O12_Duphong3_Pin, GPIO_PIN_SET);

  /*Configure GPIO pin Output Level */
  HAL_GPIO_WritePin(O18_Duphong9_GPIO_Port, O18_Duphong9_Pin, GPIO_PIN_SET);

  /*Configure GPIO pin Output Level */
  HAL_GPIO_WritePin(GPIOC, DIR_TIM3_Pin|DIR_TIM8_Pin, GPIO_PIN_RESET);

  /*Configure GPIO pin Output Level */
  HAL_GPIO_WritePin(GPIOA, DIR_TIM1_Pin|GPIO_PIN_10|DIR_NO_Pin, GPIO_PIN_RESET);

  /*Configure GPIO pin Output Level */
  HAL_GPIO_WritePin(GPIOD, O1_xilanh1_Pin|O2_xilanh2_Pin|O3_vacum_hut1_Pin|O4_vacum_hut2_Pin
                          |O5_vacum1_nha_Pin, GPIO_PIN_SET);

  /*Configure GPIO pin Output Level */
  HAL_GPIO_WritePin(GPIOB, O6_vacum2_nha_Pin|O7_Den_Xanh_Pin|O8_Den_Do_Pin|O9_Coi_Pin
                          |O10_Duphong1_Pin, GPIO_PIN_SET);

  /*Configure GPIO pins : O13_Duphong4_Pin O14_Duphong5_Pin O15_Duphong6_Pin O16_Duphong7_Pin
                           O17_Duphong8_Pin O11_Duphong2_Pin O12_Duphong3_Pin */
  GPIO_InitStruct.Pin = O13_Duphong4_Pin|O14_Duphong5_Pin|O15_Duphong6_Pin|O16_Duphong7_Pin
                          |O17_Duphong8_Pin|O11_Duphong2_Pin|O12_Duphong3_Pin;
  GPIO_InitStruct.Mode = GPIO_MODE_OUTPUT_PP;
  GPIO_InitStruct.Pull = GPIO_PULLUP;
  GPIO_InitStruct.Speed = GPIO_SPEED_FREQ_LOW;
  HAL_GPIO_Init(GPIOE, &GPIO_InitStruct);

  /*Configure GPIO pin : O18_Duphong9_Pin */
  GPIO_InitStruct.Pin = O18_Duphong9_Pin;
  GPIO_InitStruct.Mode = GPIO_MODE_OUTPUT_PP;
  GPIO_InitStruct.Pull = GPIO_PULLUP;
  GPIO_InitStruct.Speed = GPIO_SPEED_FREQ_LOW;
  HAL_GPIO_Init(O18_Duphong9_GPIO_Port, &GPIO_InitStruct);

  /*Configure GPIO pins : PC0 PC1 PC2 PC3 */
  GPIO_InitStruct.Pin = GPIO_PIN_0|GPIO_PIN_1|GPIO_PIN_2|GPIO_PIN_3;
  GPIO_InitStruct.Mode = GPIO_MODE_IT_RISING;
  GPIO_InitStruct.Pull = GPIO_NOPULL;
  HAL_GPIO_Init(GPIOC, &GPIO_InitStruct);

  /*Configure GPIO pins : I5_STOP_Pin I6_START_Pin */
  GPIO_InitStruct.Pin = I5_STOP_Pin|I6_START_Pin;
  GPIO_InitStruct.Mode = GPIO_MODE_INPUT;
  GPIO_InitStruct.Pull = GPIO_NOPULL;
  HAL_GPIO_Init(GPIOC, &GPIO_InitStruct);

  /*Configure GPIO pins : I7_RESTART_Pin I8_VACUM1_Pin PB12 */
  GPIO_InitStruct.Pin = I7_RESTART_Pin|I8_VACUM1_Pin|GPIO_PIN_12;
  GPIO_InitStruct.Mode = GPIO_MODE_INPUT;
  GPIO_InitStruct.Pull = GPIO_NOPULL;
  HAL_GPIO_Init(GPIOB, &GPIO_InitStruct);

  /*Configure GPIO pins : I9_VACUM2_Pin I_10Left_DOOR_Pin I_11_RIGHT_DOOR_Pin I12_AP_SUAT_Pin
                           I13_DU_PHONG_Pin I14_DU_PHONG2_Pin I15_DU_PHONG3_Pin I16_DU_PHONG4_Pin
                           I17_DU_PHONG5_Pin */
  GPIO_InitStruct.Pin = I9_VACUM2_Pin|I_10Left_DOOR_Pin|I_11_RIGHT_DOOR_Pin|I12_AP_SUAT_Pin
                          |I13_DU_PHONG_Pin|I14_DU_PHONG2_Pin|I15_DU_PHONG3_Pin|I16_DU_PHONG4_Pin
                          |I17_DU_PHONG5_Pin;
  GPIO_InitStruct.Mode = GPIO_MODE_INPUT;
  GPIO_InitStruct.Pull = GPIO_NOPULL;
  HAL_GPIO_Init(GPIOE, &GPIO_InitStruct);

  /*Configure GPIO pins : DIR_TIM3_Pin DIR_TIM8_Pin */
  GPIO_InitStruct.Pin = DIR_TIM3_Pin|DIR_TIM8_Pin;
  GPIO_InitStruct.Mode = GPIO_MODE_OUTPUT_PP;
  GPIO_InitStruct.Pull = GPIO_NOPULL;
  GPIO_InitStruct.Speed = GPIO_SPEED_FREQ_HIGH;
  HAL_GPIO_Init(GPIOC, &GPIO_InitStruct);

  /*Configure GPIO pin : DIR_TIM1_Pin */
  GPIO_InitStruct.Pin = DIR_TIM1_Pin;
  GPIO_InitStruct.Mode = GPIO_MODE_OUTPUT_PP;
  GPIO_InitStruct.Pull = GPIO_NOPULL;
  GPIO_InitStruct.Speed = GPIO_SPEED_FREQ_HIGH;
  HAL_GPIO_Init(DIR_TIM1_GPIO_Port, &GPIO_InitStruct);

  /*Configure GPIO pin : PA10 */
  GPIO_InitStruct.Pin = GPIO_PIN_10;
  GPIO_InitStruct.Mode = GPIO_MODE_OUTPUT_PP;
  GPIO_InitStruct.Pull = GPIO_NOPULL;
  GPIO_InitStruct.Speed = GPIO_SPEED_FREQ_MEDIUM;
  HAL_GPIO_Init(GPIOA, &GPIO_InitStruct);

  /*Configure GPIO pin : DIR_NO_Pin */
  GPIO_InitStruct.Pin = DIR_NO_Pin;
  GPIO_InitStruct.Mode = GPIO_MODE_OUTPUT_PP;
  GPIO_InitStruct.Pull = GPIO_NOPULL;
  GPIO_InitStruct.Speed = GPIO_SPEED_FREQ_LOW;
  HAL_GPIO_Init(DIR_NO_GPIO_Port, &GPIO_InitStruct);

  /*Configure GPIO pins : O1_xilanh1_Pin O2_xilanh2_Pin O3_vacum_hut1_Pin O4_vacum_hut2_Pin
                           O5_vacum1_nha_Pin */
  GPIO_InitStruct.Pin = O1_xilanh1_Pin|O2_xilanh2_Pin|O3_vacum_hut1_Pin|O4_vacum_hut2_Pin
                          |O5_vacum1_nha_Pin;
  GPIO_InitStruct.Mode = GPIO_MODE_OUTPUT_PP;
  GPIO_InitStruct.Pull = GPIO_PULLUP;
  GPIO_InitStruct.Speed = GPIO_SPEED_FREQ_LOW;
  HAL_GPIO_Init(GPIOD, &GPIO_InitStruct);

  /*Configure GPIO pins : O6_vacum2_nha_Pin O7_Den_Xanh_Pin O8_Den_Do_Pin O9_Coi_Pin
                           O10_Duphong1_Pin */
  GPIO_InitStruct.Pin = O6_vacum2_nha_Pin|O7_Den_Xanh_Pin|O8_Den_Do_Pin|O9_Coi_Pin
                          |O10_Duphong1_Pin;
  GPIO_InitStruct.Mode = GPIO_MODE_OUTPUT_PP;
  GPIO_InitStruct.Pull = GPIO_PULLUP;
  GPIO_InitStruct.Speed = GPIO_SPEED_FREQ_LOW;
  HAL_GPIO_Init(GPIOB, &GPIO_InitStruct);

  /* EXTI interrupt init*/
  HAL_NVIC_SetPriority(EXTI0_IRQn, 0, 0);
  HAL_NVIC_EnableIRQ(EXTI0_IRQn);

  HAL_NVIC_SetPriority(EXTI1_IRQn, 0, 0);
  HAL_NVIC_EnableIRQ(EXTI1_IRQn);

  HAL_NVIC_SetPriority(EXTI2_IRQn, 0, 0);
  HAL_NVIC_EnableIRQ(EXTI2_IRQn);

  HAL_NVIC_SetPriority(EXTI3_IRQn, 0, 0);
  HAL_NVIC_EnableIRQ(EXTI3_IRQn);

}

/* USER CODE BEGIN 4 */
void HAL_GPIO_EXTI_Callback(uint16_t GPIO_Pin)
{

}
/* USER CODE END 4 */

void Error_Handler(void)
{
  __disable_irq();
  while (1)
  {
  }
}
